# VPAC0_COMMON_0_IVPAC_TOP_0_CFG_SLV_PAR_VPAC_VISS0_S_VBUSP_VISS_CAC_S_VBUSP_MMRCFG_CAC register map
Vendor: Texas Instruments
Peripheral module from a debugger description file (folder am62A).
Registers are 32-bit, read-write, reset 0x0 unless marked. A register's access mark holds for its fields unless they carry their own. Offsets are as the file gives them; lines under a group give offsets from that group; [hi:lo] are bit positions; {n}, {i} and the like mark numbered series; 'fields as' and 'values as' point back to an identical list; <NAME> marks a mode.

## VPAC0_COMMON_0_IVPAC_TOP_0_CFG_SLV_PAR_VPAC_VISS0_S_VBUSP_VISS_CAC_S_VBUSP_MMRCFG_CAC
0x04 IVPAC_TOP_0__CFG_SLV__PAR_VPAC_VISS0__S_VBUSP__VISS_CAC__S_VBUSP__MMR__MMRCFG__CAC_REGS_CTRL — Control Register to Enable/Disable and select modes of operation
  [11:8] COLOR_EN — Enable for CAC processing in 2x2 pixel grid. bit[0] - row[0]col[0] bit[1] - row[0]col[1] bit[2] - row[1]col[0] bit[3] - row[1]col[1]. One pixel should be enabled in each row of 2x2. 10 or 01 combinations are allowed in each row. Value should be one of 5, 6, 9, 10
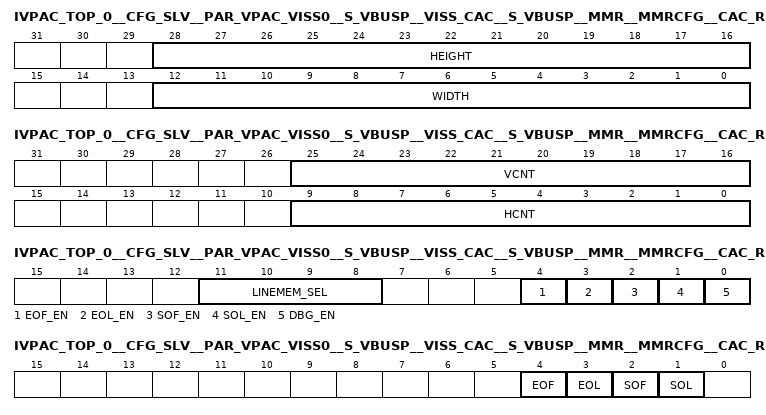
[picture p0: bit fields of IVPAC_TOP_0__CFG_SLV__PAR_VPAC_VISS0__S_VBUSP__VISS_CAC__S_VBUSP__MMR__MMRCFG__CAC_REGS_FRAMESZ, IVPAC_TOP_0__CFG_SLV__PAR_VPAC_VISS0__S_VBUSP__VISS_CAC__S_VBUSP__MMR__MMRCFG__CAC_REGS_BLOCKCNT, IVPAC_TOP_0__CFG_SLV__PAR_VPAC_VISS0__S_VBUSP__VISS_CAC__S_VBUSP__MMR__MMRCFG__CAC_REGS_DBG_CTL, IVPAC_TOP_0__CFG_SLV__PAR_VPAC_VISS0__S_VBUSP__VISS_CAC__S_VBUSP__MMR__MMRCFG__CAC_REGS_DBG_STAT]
0x08 IVPAC_TOP_0__CFG_SLV__PAR_VPAC_VISS0__S_VBUSP__VISS_CAC__S_VBUSP__MMR__MMRCFG__CAC_REGS_FRAMESZ — Actual frame size is configured value + 1
  [28:16] HEIGHT — Number of Lines per frame. Actual Frame height is HEIGHT +1. Actual frame height should minimum of 32 and multiple of 2
  [12:0] WIDTH — Number of pixels per line. Actual Frame width is WIDTH +1. Actual frame width should minimum of 64 and multiple of 2
0x0C IVPAC_TOP_0__CFG_SLV__PAR_VPAC_VISS0__S_VBUSP__VISS_CAC__S_VBUSP__MMR__MMRCFG__CAC_REGS_BLOCKSZ — Size of Block and each block will have 2 LUT entries with displacement value
  [7:0] SIZE — Height and Width of Subsampled Block. Each block will have 2 displacement entries for SIZExSIZE block ; one for even line and other for odd line. Minimum of 8 and maximum of 128. Should be multiple of 4
0x10 IVPAC_TOP_0__CFG_SLV__PAR_VPAC_VISS0__S_VBUSP__VISS_CAC__S_VBUSP__MMR__MMRCFG__CAC_REGS_BLOCKCNT — LUT Grid size. Should cover frame size plus 1 for interpolation. VCNT * HCNT <= 2048
  [25:16] VCNT — LUT Grid heighti, i.e. no. of blocks in vertical direction. (VCNT-1)* BLOCKSZ.SIZE >= frame_height and max value is 512
  [9:0] HCNT — LUT Grid width, i.e. no. of blocks in horizontal direction. (HCNT-1)* BLOCKSZ.SIZE >= frame_width and max value is 512
0x80 IVPAC_TOP_0__CFG_SLV__PAR_VPAC_VISS0__S_VBUSP__VISS_CAC__S_VBUSP__MMR__MMRCFG__CAC_REGS_INT_STAT access not given — Set on internal interupt event and clr by SW
  [0] LUT_CFG_ERR — status/clear for mmr configuration error. Set when Config access happen to LUT memory in the middle of processing (access R/W1TC)
0x100 IVPAC_TOP_0__CFG_SLV__PAR_VPAC_VISS0__S_VBUSP__VISS_CAC__S_VBUSP__MMR__MMRCFG__CAC_REGS_DBG_CTL — Control the memory access selection
  [11:8] LINEMEM_SEL — 0-6: CAC corrected line memory. i.e. EnLine0..6 7-9: Bypassed pixel Line memory. i.e. BypLine0..2
  [4] EOF_EN — Enable for EOF at CAC output
  [3] EOL_EN — Enable for EOL at CAC output
  [2] SOF_EN — Enable for SOF at CAC input
  [1] SOL_EN — Enable for SOL at CAC input
  [0] DBG_EN — Enable debug features, set to '0' to disable all debug events
0x104 IVPAC_TOP_0__CFG_SLV__PAR_VPAC_VISS0__S_VBUSP__VISS_CAC__S_VBUSP__MMR__MMRCFG__CAC_REGS_DBG_STAT access not given — Set/Clear for CAC debug events
  [4] EOF — Status/Clear for EOF at CAC output. Set on EOF at CAC output (access R/W1TC)
  [3] EOL — Status/Clear for EOL at CAC output. Set on EOL at CAC output (access R/W1TC)
  [2] SOF — Status/Clear for SOF at CAC input. Set on SOF at CAC input (access R/W1TC)
  [1] SOL — Status/Clear for SOL at CAC input. Set on SOL at CAC input (access R/W1TC)
